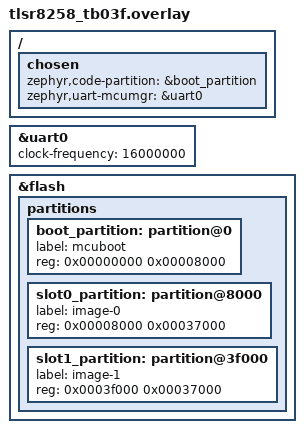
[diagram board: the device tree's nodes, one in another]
/*
 * Copyright (c) 2026 Ivan Belokobylskiy
 *
 * SPDX-License-Identifier: Apache-2.0
 */

/*
 * MCUboot sits at flash 0, where the boot ROM finds the "KNLT" boot mark.
 * The two image slots are equal-sized for the overwrite-only upgrade and
 * end where the factory IEEE address sector begins.
 */

/ {
	chosen {
		zephyr,code-partition = &boot_partition;
		zephyr,uart-mcumgr = &uart0;
	};
};

/*
 * The loader runs on the reset clock, 16 MHz, not the 24 MHz the SoC dtsi
 * assumes for the UART, which would make every baud rate 2/3 of the one asked.
 */
&uart0 {
	clock-frequency = <16000000>;
};

&flash {
	partitions {
		/delete-node/ partition@0;

		boot_partition: partition@0 {
			label = "mcuboot";
			reg = <0x00000000 0x00008000>;
		};

		slot0_partition: partition@8000 {
			label = "image-0";
			reg = <0x00008000 0x00037000>;
		};

		slot1_partition: partition@3f000 {
			label = "image-1";
			reg = <0x0003f000 0x00037000>;
		};
	};
};
